VERSION "Independent Song PLUS observation candidates; no transmit definitions"

NS_ :

BS_:
BU_: OBSERVED

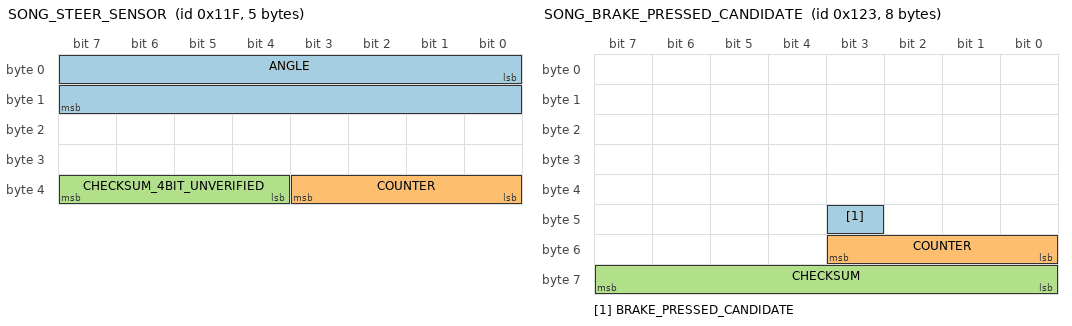
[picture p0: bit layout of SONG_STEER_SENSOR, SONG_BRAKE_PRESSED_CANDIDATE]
BO_ 287 SONG_STEER_SENSOR: 5 OBSERVED
 SG_ ANGLE : 0|16@1- (0.1,0) [-3276.8|3276.7] "deg" OBSERVED
 SG_ COUNTER : 32|4@1+ (1,0) [0|15] "" OBSERVED
 SG_ CHECKSUM_4BIT_UNVERIFIED : 36|4@1+ (1,0) [0|15] "" OBSERVED

BO_ 291 SONG_BRAKE_PRESSED_CANDIDATE: 8 OBSERVED
 SG_ BRAKE_PRESSED_CANDIDATE : 43|1@1+ (1,0) [0|1] "" OBSERVED
 SG_ COUNTER : 48|4@1+ (1,0) [0|15] "" OBSERVED
 SG_ CHECKSUM : 56|8@1+ (1,0) [0|255] "" OBSERVED

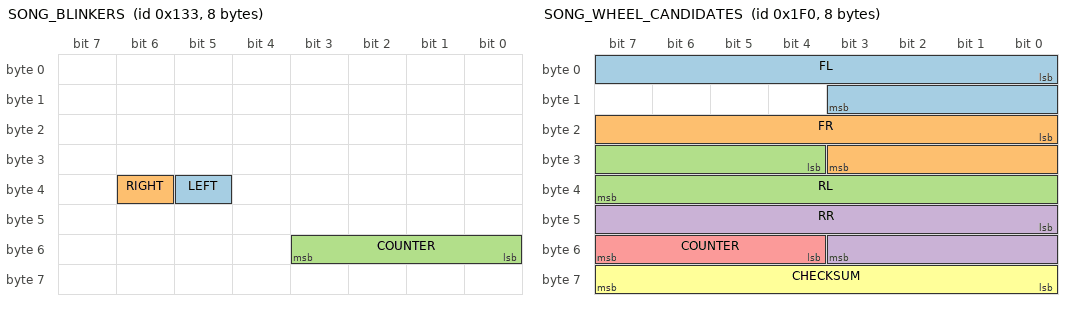
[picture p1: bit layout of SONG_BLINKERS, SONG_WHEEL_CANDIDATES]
BO_ 307 SONG_BLINKERS: 8 OBSERVED
 SG_ LEFT : 37|1@1+ (1,0) [0|1] "" OBSERVED
 SG_ RIGHT : 38|1@1+ (1,0) [0|1] "" OBSERVED
 SG_ COUNTER : 48|4@1+ (1,0) [0|15] "" OBSERVED

BO_ 496 SONG_WHEEL_CANDIDATES: 8 OBSERVED
 SG_ FL : 0|12@1+ (0.02013888888888889,0) [0|82.46875] "m/s" OBSERVED
 SG_ FR : 16|12@1+ (0.02013888888888889,0) [0|82.46875] "m/s" OBSERVED
 SG_ RL : 28|12@1+ (0.02013888888888889,0) [0|82.46875] "m/s" OBSERVED
 SG_ RR : 40|12@1+ (0.02013888888888889,0) [0|82.46875] "m/s" OBSERVED
 SG_ COUNTER : 52|4@1+ (1,0) [0|15] "" OBSERVED
 SG_ CHECKSUM : 56|8@1+ (1,0) [0|255] "" OBSERVED

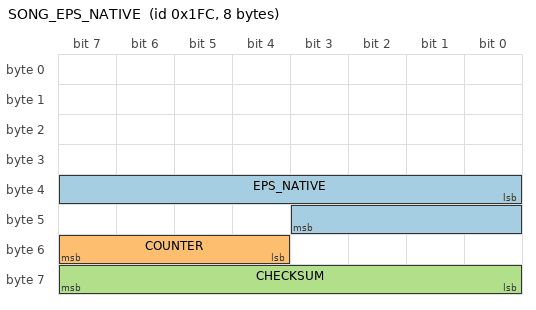
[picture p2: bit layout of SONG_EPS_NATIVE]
BO_ 508 SONG_EPS_NATIVE: 8 OBSERVED
 SG_ EPS_NATIVE : 32|12@1- (1,0) [-2048|2047] "native" OBSERVED
 SG_ COUNTER : 52|4@1+ (1,0) [0|15] "" OBSERVED
 SG_ CHECKSUM : 56|8@1+ (1,0) [0|255] "" OBSERVED

BO_ 544 SONG_CRUISE_STANDSTILL_CANDIDATE: 8 OBSERVED
 SG_ CRUISE_STANDSTILL_CANDIDATE : 8|1@1+ (1,0) [0|1] "" OBSERVED

BO_ 578 SONG_GEAR_CANDIDATE: 8 OBSERVED
 SG_ GEAR_RAW : 40|3@1+ (1,0) [0|7] "" OBSERVED

BO_ 834 SONG_PEDAL_VALUES: 8 OBSERVED
 SG_ GAS_RAW : 0|8@1+ (1,0) [0|255] "" OBSERVED
 SG_ GAS : 0|8@1+ (0.01,0) [0|2.55] "legacy normalized" OBSERVED
 SG_ BRAKE : 8|8@1+ (0.01,0) [0|2.55] "legacy normalized" OBSERVED
 SG_ COUNTER : 52|4@1+ (1,0) [0|15] "" OBSERVED
 SG_ CHECKSUM : 56|8@1+ (1,0) [0|255] "" OBSERVED
